AUTOSAR XML (schema 4-2-1)
package /ComponentTypes
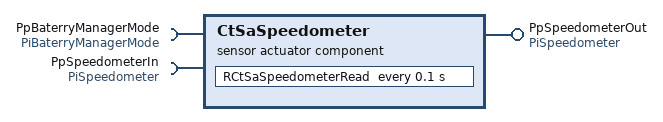
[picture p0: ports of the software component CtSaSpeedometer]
  sensor actuator sw component type CtSaSpeedometer
    provide port PpSpeedometerOut: nonqueued-sender-com-spec{data-element=DeSpeedometer, init-value=0}, provided-interface=PiSpeedometer
    require port PpBaterryManagerMode: mode-switch-receiver-com-spec{enhanced-mode-api=false, supports-asynchronous-mode-switch=false}, required-interface=PiBaterryManagerMode
    require port PpSpeedometerIn: nonqueued-receiver-com-spec{data-element=DeSpeedometer, filter=data-filter-type=ALWAYS, init-value=0}, required-interface=PiSpeedometer
    behavior CtSaSpeedometer_InternalBehavior
      timing event TMT_RCtSaSpeedometerRead: disabled-mode=PpBaterryManagerMode.Mode.BATTERY_LOW, start-on-event=RCtSaSpeedometerRead, period=0.1
      runnable RCtSaSpeedometerRead
        data-receive-point-by-arguments:
          access REC_PpSpeedometerIn_DeSpeedometer: accessed-variable=PpSpeedometerIn.DeSpeedometer
        data-send-points:
          access SEND_PpSpeedometerOut_DeSpeedometer: accessed-variable=PpSpeedometerOut.DeSpeedometer
  swc implementation CtSaSpeedometer_Implementation: behavior=CtSaSpeedometer_InternalBehavior
    code-descriptors:
      code Default: artifact-descriptors=autosar-engineering-object={short-label=Default, category=SWSRC}
